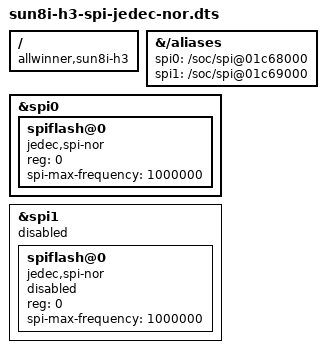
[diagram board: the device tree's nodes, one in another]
/dts-v1/ /plugin/;

/ {
	compatible = "allwinner,sun8i-h3";

	fragment@0 {
		target-path = "/aliases";
		__overlay__ {
			spi0 = "/soc/spi@01c68000";
			spi1 = "/soc/spi@01c69000";
		};
	};

	fragment@1 {
		target = <&spi0>;
		__overlay__ {
			status = "okay";
			#address-cells = <1>;
			#size-cells = <0>;
			spiflash@0 {
				compatible = "jedec,spi-nor";
				reg = <0>;
				spi-max-frequency = <1000000>;
				status = "okay";
			};
		};
	};

	fragment@2 {
		target = <&spi1>;
		__overlay__ {
			status = "disabled";
			#address-cells = <1>;
			#size-cells = <0>;
			spiflash@0 {
				compatible = "jedec,spi-nor";
				status = "disabled";
				reg = <0>;
				spi-max-frequency = <1000000>;
			};
		};
	};
};
